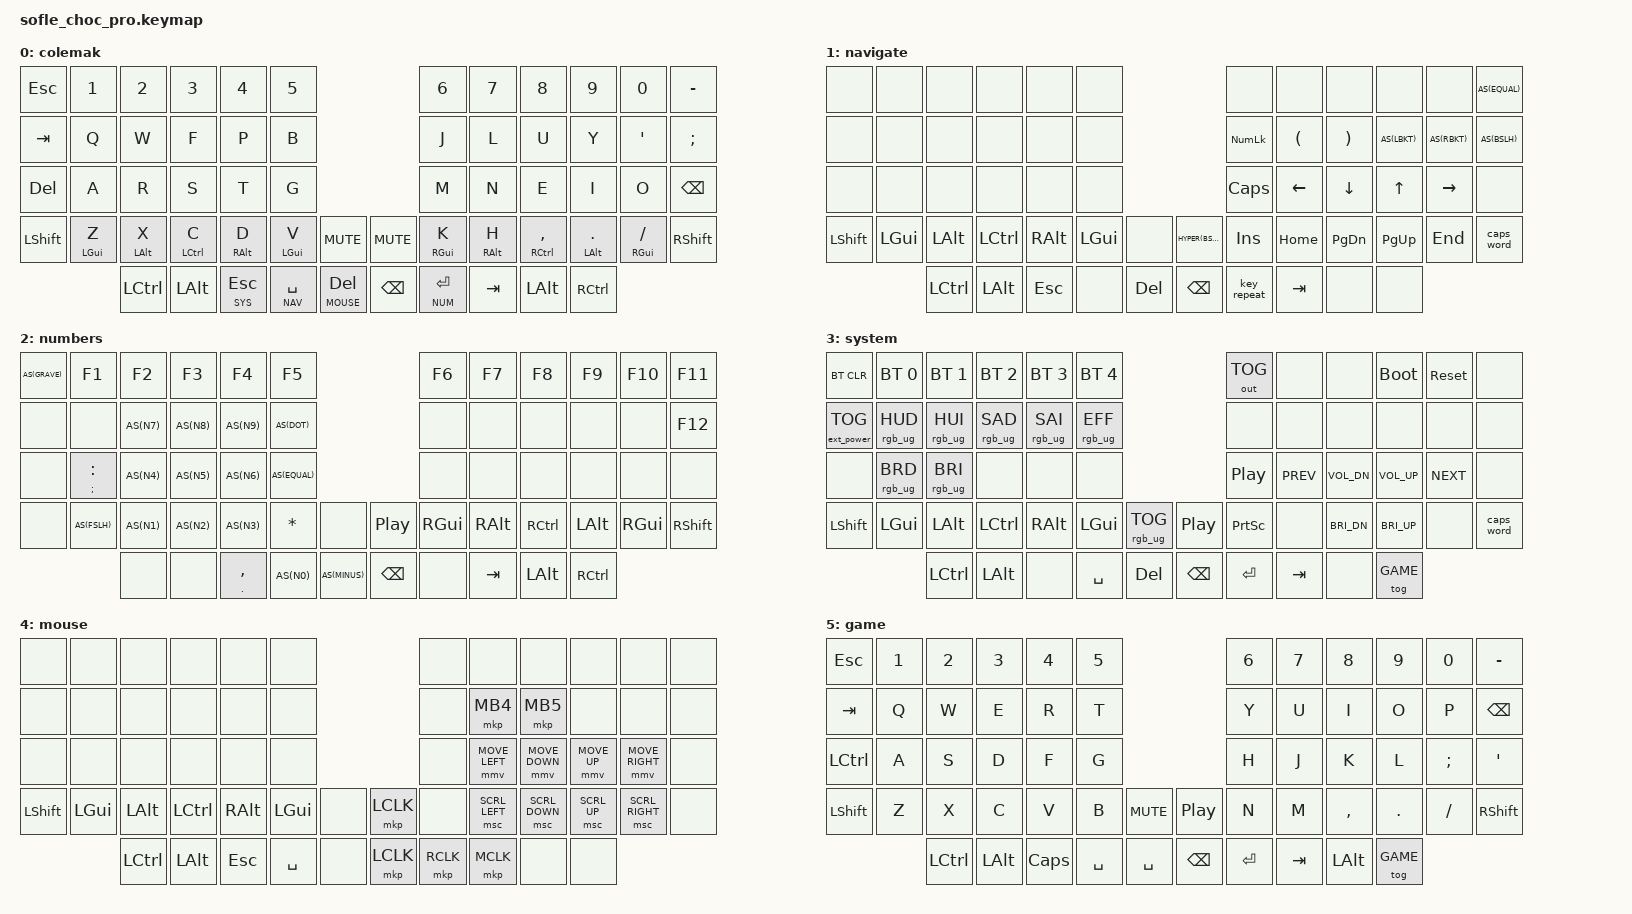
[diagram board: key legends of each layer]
/*
* Copyright (c) 2020 The ZMK Contributors
*
* SPDX-License-Identifier: MIT
*/

#include <behaviors.dtsi>
#include <dt-bindings/zmk/keys.h>
#include <dt-bindings/zmk/bt.h>
#include <dt-bindings/zmk/rgb.h>
#include <dt-bindings/zmk/ext_power.h>
#include <dt-bindings/zmk/outputs.h>
// Pointer speed for the MOVE_* keys (stock 600 px/s is too slow).
#define ZMK_POINTING_DEFAULT_MOVE_VAL 1200
#include <dt-bindings/zmk/pointing.h>
#include <zephyr/dt-bindings/input/input-event-codes.h>

#define BASE 0
#define NAV 1
#define NUM 2
#define SYS 3
#define MOUSE 4
#define GAME 5

// Key positions per hand, row by row, following default_transform in
// boards/arm/sofle_choc_pro/sofle_choc_pro.dtsi (rows of 12 12 12 14 10 keys).
#define KEYS_L   0 1 2 3 4 5   12 13 14 15 16 17   24 25 26 27 28 29   36 37 38 39 40 41 42
#define KEYS_R   6 7 8 9 10 11 18 19 20 21 22 23   30 31 32 33 34 35   43 44 45 46 47 48 49
#define THUMBS_L 50 51 52 53 54
#define THUMBS_R 55 56 57 58 59

// Tap then hold within this window repeats the tap key instead of holding.
#define QUICK_TAP_MS 175

// Hyper (Cmd+Ctrl+Alt+Shift): collision-free chords for host-bound workspace actions
// (AeroSpace on macOS; bind the same chords in the Linux window manager). Contains
// both Ctrl and Cmd, so the Mac-side Ctrl/Cmd swap does not affect it.
#define HYPER(k) LS(LC(LA(LG(k))))

// Auto-shift: tap for the key, hold for its shifted form; double-tap-and-hold repeats the key.
#define AS(k) &ht LS(k) k

// Thumb layer-taps: the layer wins on a fast thumb+key roll.
&lt {
  flavor = "balanced";
  quick-tap-ms = <QUICK_TAP_MS>;
};

// Pointer ramps from zero to full speed in 200 ms (stock 300) for a quicker response.
&mmv {
  time-to-max-speed-ms = <200>;
};

/ {

  behaviors {
    // Bottom-row mod-taps: tap for the letter, hold for the modifier. A hold only
    // triggers when the other hand presses the next key, and a press within 150 ms
    // of the previous key is always a tap, so same-hand rolls never become modifiers.
    hml: homerow_mod_left {
      compatible = "zmk,behavior-hold-tap";
      #binding-cells = <2>;
      flavor = "balanced";
      tapping-term-ms = <200>;
      quick-tap-ms = <QUICK_TAP_MS>;
      require-prior-idle-ms = <150>;
      hold-trigger-key-positions = <KEYS_R THUMBS_R>;
      hold-trigger-on-release;
      bindings = <&kp>, <&kp>;
    };

    hmr: homerow_mod_right {
      compatible = "zmk,behavior-hold-tap";
      #binding-cells = <2>;
      flavor = "balanced";
      tapping-term-ms = <200>;
      quick-tap-ms = <QUICK_TAP_MS>;
      require-prior-idle-ms = <150>;
      hold-trigger-key-positions = <KEYS_L THUMBS_L>;
      hold-trigger-on-release;
      bindings = <&kp>, <&kp>;
    };

    // Tap-preferred hold-tap: &ht <hold> <tap>. AS() uses it for auto-shift.
    ht: hold_tap {
      compatible = "zmk,behavior-hold-tap";
      #binding-cells = <2>;
      flavor = "tap-preferred";
      tapping-term-ms = <200>;
      quick-tap-ms = <QUICK_TAP_MS>;
      bindings = <&kp>, <&kp>;
    };

    // &msc scrolls 10 units/s on a 16 ms tick (0.16 per tick), so a short encoder
    // tap never sends a whole unit; 100 units/s on a 10 ms tick sends exactly one.
    enc_scroll_axis: enc_scroll_axis {
      compatible = "zmk,behavior-input-two-axis";
      #binding-cells = <1>;
      x-input-code = <INPUT_REL_HWHEEL>;
      y-input-code = <INPUT_REL_WHEEL>;
      trigger-period-ms = <10>;
      time-to-max-speed-ms = <0>;
    };

    scroll_encoder: scroll_encoder {
      compatible = "zmk,behavior-sensor-rotate";
      #sensor-binding-cells = <0>;
      bindings = <&enc_scroll_axis MOVE_Y(100)>, <&enc_scroll_axis MOVE_Y(-100)>;
      tap-ms = <12>;
    };
  };

  enc_scroll_input_listener {
    compatible = "zmk,input-listener";
    device = <&enc_scroll_axis>;
  };

  // sensor-bindings: <left (not fitted; plain switch)> <right>. Pairs are listed
  // counter-clockwise first, as in the stock board keymap: this board reports
  // rotation reversed. display-name must fit the 68-px Montserrat-14 label drawn
  // by boards/shields/sharp_mip/widgets/status.c.
  keymap {
    compatible = "zmk,keymap";

    default_layer {
      display-name = "colemak";
      // -------------------------------------------------------------------------------------------------------------------------------------------------------------------------
      // |    ESC    |     1     |     2     |     3     |     4     |     5     |                       |     6     |     7     |     8     |     9     |     0     |     -     |
      // |    TAB    |     Q     |     W     |     F     |     P     |     B     |                       |     J     |     L     |     U     |     Y     |     '     |     ;     |
      // |    DEL    |     A     |     R     |     S     |     T     |     G     |                       |     M     |     N     |     E     |     I     |     O     |    BSPC   |
      // |   SHIFT   |   GUI/Z   |   ALT/X   |   CTRL/C  |   AGR/D   |   GUI/V   |    MUTE   |    MUTE   |   GUI/K   |   AGR/H   |   CTRL/,  |   ALT/.   |   GUI//   |   SHIFT   |
      //                         |    CTRL   |    ALT    |  SYS/ESC  | NAV/SPACE | MOUSE/DEL |    BSPC   | NUM/ENTER |    TAB    |    ALT    |    CTRL   |
      // Right encoder turn: mouse scroll
      bindings = <
        &kp ESC           &kp N1            &kp N2            &kp N3            &kp N4            &kp N5                                                &kp N6            &kp N7            &kp N8            &kp N9            &kp N0            &kp MINUS
        &kp TAB           &kp Q             &kp W             &kp F             &kp P             &kp B                                                 &kp J             &kp L             &kp U             &kp Y             &kp SQT           &kp SEMI
        &kp DEL           &kp A             &kp R             &kp S             &kp T             &kp G                                                 &kp M             &kp N             &kp E             &kp I             &kp O             &kp BSPC
        &kp LSHFT         &hml LGUI Z       &hml LALT X       &hml LCTRL C      &hml RALT D       &hml LGUI V       &kp C_MUTE        &kp C_MUTE        &hmr RGUI K       &hmr RALT H       &hmr RCTRL COMMA  &hmr LALT DOT     &hmr RGUI FSLH    &kp RSHFT
                                            &kp LCTRL         &kp LALT          &lt SYS ESC       &lt NAV SPACE     &lt MOUSE DEL     &kp BSPC          &lt NUM RET       &kp TAB           &kp LALT          &kp RCTRL
      >;

      sensor-bindings = <&inc_dec_kp C_VOL_DN C_VOL_UP &scroll_encoder>;
    };

    nav_layer {
      display-name = "navigate";
      // -------------------------------------------------------------------------------------------------------------------------------
      // |        |        |        |        |        |        |                 |        |        |        |        |        |   =    |
      // |        |        |        |        |        |        |                 | NUMLK  |   (    |   )    |   [    |   ]    |   \    |
      // |        |        |        |        |        |        |                 |  CAPS  |  LEFT  |  DOWN  |   UP   | RIGHT  |        |
      // | SHIFT  |  GUI   |  ALT   |  CTRL  |  AGR   |  GUI   |        | WS_BF  |  INS   |  HOME  |  PGDN  |  PGUP  |  END   | CAPSW  |
      //                   |  CTRL  |  ALT   |  ESC   |        |  DEL   |  BSPC  | REPEAT |  TAB   |        |        |
      // Hold [ ] = \ for { } + |.
      // Right encoder turn: workspace prev / next (Hyper+[ / Hyper+]).
      bindings = <
        &none            &none            &none            &none            &none            &none                                              &none            &none            &none            &none            &none            AS(EQUAL)
        &none            &none            &none            &none            &none            &none                                              &kp KP_NUM       &kp LPAR         &kp RPAR         AS(LBKT)         AS(RBKT)         AS(BSLH)
        &none            &none            &none            &none            &none            &none                                              &kp CAPS         &kp LEFT         &kp DOWN         &kp UP           &kp RIGHT        &none
        &kp LSHFT        &kp LGUI         &kp LALT         &kp LCTRL        &kp RALT         &kp LGUI         &none            &kp HYPER(BSLH)  &kp INS          &kp HOME         &kp PG_DN        &kp PG_UP        &kp END          &caps_word
                                          &kp LCTRL        &kp LALT         &kp ESC          &none            &kp DEL          &kp BSPC         &key_repeat      &kp TAB          &none            &none
      >;

      sensor-bindings = <&inc_dec_kp C_VOL_DN C_VOL_UP &inc_dec_kp HYPER(LBKT) HYPER(RBKT)>;
    };

    num_layer {
      display-name = "numbers";
      // -----------------------------------------------------------------------------------------------------------------
      // |   `   |   F1  |   F2  |   F3  |   F4  |   F5  |               |   F6  |   F7  |   F8  |   F9  |  F10  |  F11  |
      // |       |       |   7   |   8   |   9   |   .   |               |       |       |       |       |       |  F12  |
      // |       |   :   |   4   |   5   |   6   |   =   |               |       |       |       |       |       |       |
      // |       |   /   |   1   |   2   |   3   |   *   |       |  PLAY |  GUI  |  AGR  |  CTRL |  ALT  |  GUI  | SHIFT |
      //                 |       |       |   ,   |   0   |   -   |  BSPC |       |  TAB  |  ALT  |  CTRL |
      // Hold : for ; and , for .
      // Right encoder turn: left / right arrow
      bindings = <
        AS(GRAVE)       &kp F1          &kp F2          &kp F3          &kp F4          &kp F5                                          &kp F6          &kp F7          &kp F8          &kp F9          &kp F10         &kp F11
        &none           &none           AS(N7)          AS(N8)          AS(N9)          AS(DOT)                                         &none           &none           &none           &none           &none           &kp F12
        &none           &ht SEMI COLON  AS(N4)          AS(N5)          AS(N6)          AS(EQUAL)                                       &none           &none           &none           &none           &none           &none
        &none           AS(FSLH)        AS(N1)          AS(N2)          AS(N3)          &kp ASTRK       &none           &kp C_PP        &kp RGUI        &kp RALT        &kp RCTRL       &kp LALT        &kp RGUI        &kp RSHFT
                                        &none           &none           &ht DOT COMMA   AS(N0)          AS(MINUS)       &kp BSPC        &none           &kp TAB         &kp LALT        &kp RCTRL
      >;

      sensor-bindings = <&inc_dec_kp C_VOL_DN C_VOL_UP &inc_dec_kp LEFT RIGHT>;
    };

    sys_layer {
      display-name = "system";
      // ---------------------------------------------------------------------------------------------------------------------------------------------
      // |  BTCLR  |   BT1   |   BT2   |   BT3   |   BT4   |   BT5   |                   | OUT_TOG |         |         | BOOTLDR |  RESET  |         |
      // |  EXTPWR | RGB_HUD | RGB_HUI | RGB_SAD | RGB_SAI | RGB_EFF |                   |         |         |         |         |         |         |
      // |         | RGB_BRD | RGB_BRI |         |         |         |                   |   PLAY  |   PREV  |  VOL_DN |  VOL_UP |   NEXT  |         |
      // |  SHIFT  |   GUI   |   ALT   |   CTRL  |   AGR   |   GUI   | RGB_TOG |   PLAY  |  PRTSCR |         |  BRI_DN |  BRI_UP |         |  CAPSW  |
      //                     |   CTRL  |   ALT   |         |  SPACE  |   DEL   |   BSPC  |  ENTER  |   TAB   |         |   GAME  |
      // Right encoder turn: volume
      bindings = <
        &bt BT_CLR         &bt BT_SEL 0       &bt BT_SEL 1       &bt BT_SEL 2       &bt BT_SEL 3       &bt BT_SEL 4                                             &out OUT_TOG       &none              &none              &bootloader        &sys_reset         &none
        &ext_power EP_TOG  &rgb_ug RGB_HUD    &rgb_ug RGB_HUI    &rgb_ug RGB_SAD    &rgb_ug RGB_SAI    &rgb_ug RGB_EFF                                          &none              &none              &none              &none              &none              &none
        &none              &rgb_ug RGB_BRD    &rgb_ug RGB_BRI    &none              &none              &none                                                    &kp C_PP           &kp C_PREV         &kp C_VOL_DN       &kp C_VOL_UP       &kp C_NEXT         &none
        &kp LSHFT          &kp LGUI           &kp LALT           &kp LCTRL          &kp RALT           &kp LGUI           &rgb_ug RGB_TOG    &kp C_PP           &kp PSCRN          &none              &kp C_BRI_DN       &kp C_BRI_UP       &none              &caps_word
                                              &kp LCTRL          &kp LALT           &none              &kp SPACE          &kp DEL            &kp BSPC           &kp RET            &kp TAB            &none              &tog GAME
      >;

      sensor-bindings = <&inc_dec_kp C_VOL_DN C_VOL_UP &inc_dec_kp C_VOL_DN C_VOL_UP>;
    };

    mouse_layer {
      display-name = "mouse";
      // -----------------------------------------------------------------------------------------------------------------
      // |       |       |       |       |       |       |               |       |       |       |       |       |       |
      // |       |       |       |       |       |       |               |       |  BACK |  FWD  |       |       |       |
      // |       |       |       |       |       |       |               |       |  LEFT |  DOWN |   UP  | RIGHT |       |
      // | SHIFT |  GUI  |  ALT  |  CTRL |  AGR  |  GUI  |       |  LCLK |       | SCR_LT| SCR_DN| SCR_UP| SCR_RT|       |
      //                 |  CTRL |  ALT  |  ESC  | SPACE |       |  LCLK |  RCLK |  MCLK |       |       |
      // Right encoder turn: mouse scroll
      bindings = <
        &none            &none            &none            &none            &none            &none                                              &none            &none            &none            &none            &none            &none
        &none            &none            &none            &none            &none            &none                                              &none            &mkp MB4         &mkp MB5         &none            &none            &none
        &none            &none            &none            &none            &none            &none                                              &none            &mmv MOVE_LEFT   &mmv MOVE_DOWN   &mmv MOVE_UP     &mmv MOVE_RIGHT  &none
        &kp LSHFT        &kp LGUI         &kp LALT         &kp LCTRL        &kp RALT         &kp LGUI         &none            &mkp LCLK        &none            &msc SCRL_LEFT   &msc SCRL_DOWN   &msc SCRL_UP     &msc SCRL_RIGHT  &none
                                          &kp LCTRL        &kp LALT         &kp ESC          &kp SPACE        &none            &mkp LCLK        &mkp RCLK        &mkp MCLK        &none            &none
      >;

      sensor-bindings = <&inc_dec_kp C_VOL_DN C_VOL_UP &scroll_encoder>;
    };

    game_layer {
      display-name = "game";
      // -----------------------------------------------------------------------------------------------------------------
      // |  ESC  |   1   |   2   |   3   |   4   |   5   |               |   6   |   7   |   8   |   9   |   0   |   -   |
      // |  TAB  |   Q   |   W   |   E   |   R   |   T   |               |   Y   |   U   |   I   |   O   |   P   |  BSPC |
      // |  CTRL |   A   |   S   |   D   |   F   |   G   |               |   H   |   J   |   K   |   L   |   ;   |   '   |
      // | SHIFT |   Z   |   X   |   C   |   V   |   B   |  MUTE |  PLAY |   N   |   M   |   ,   |   .   |   /   | SHIFT |
      //                 |  CTRL |  ALT  |  CAPS | SPACE | SPACE |  BSPC | ENTER |  TAB  |  ALT  |  GAME |
      // Toggled from SYS; no layer keys here, so only BASE is ever active underneath.
      // Plain keys only: held keys repeat and ESC fires on press.
      // Right encoder turn: volume
      bindings = <
        &kp ESC     &kp N1      &kp N2      &kp N3      &kp N4      &kp N5                              &kp N6      &kp N7      &kp N8      &kp N9      &kp N0      &kp MINUS
        &kp TAB     &kp Q       &kp W       &kp E       &kp R       &kp T                               &kp Y       &kp U       &kp I       &kp O       &kp P       &kp BSPC
        &kp LCTRL   &kp A       &kp S       &kp D       &kp F       &kp G                               &kp H       &kp J       &kp K       &kp L       &kp SEMI    &kp SQT
        &kp LSHFT   &kp Z       &kp X       &kp C       &kp V       &kp B       &kp C_MUTE  &kp C_PP    &kp N       &kp M       &kp COMMA   &kp DOT     &kp FSLH    &kp RSHFT
                                &kp LCTRL   &kp LALT    &kp CAPS    &kp SPACE   &kp SPACE   &kp BSPC    &kp RET     &kp TAB     &kp LALT    &tog GAME
      >;

      sensor-bindings = <&inc_dec_kp C_VOL_DN C_VOL_UP &inc_dec_kp C_VOL_DN C_VOL_UP>;
    };
  };
};
